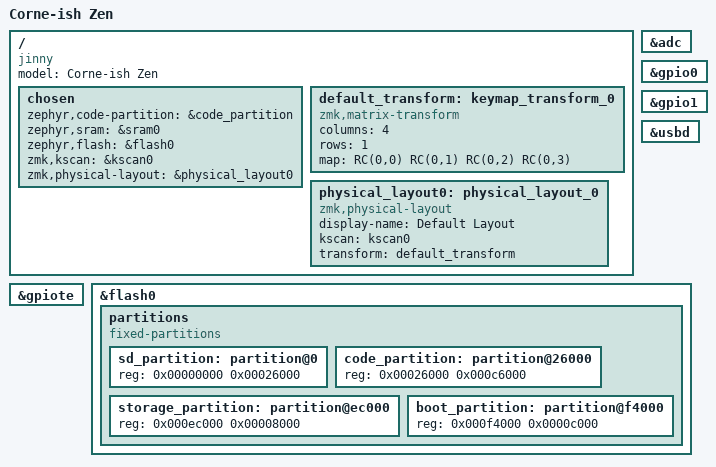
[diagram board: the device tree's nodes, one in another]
/*
*
* Copyright (c) 2021 Darryl deHaan
* SPDX-License-Identifier: MIT
*
*/

/dts-v1/;
#include <nordic/nrf52840_qiaa.dtsi>

#include <dt-bindings/zmk/matrix_transform.h>

/ {
    model = "Corne-ish Zen";
    compatible = "jinny";

    chosen {
        zephyr,code-partition = &code_partition;
        zephyr,sram = &sram0;
        zephyr,flash = &flash0;
        zmk,kscan = &kscan0;
        zmk,physical-layout = &physical_layout0;
    };

    default_transform: keymap_transform_0 {
        compatible = "zmk,matrix-transform";
        columns = <4>;
        rows = <1>;

            // | SW1  | SW2  | SW3  | SW4
                    map = <
            RC(0,0) RC(0,1) RC(0,2) RC(0,3)
        >;
    };

    physical_layout0: physical_layout_0 {
        compatible = "zmk,physical-layout";
        display-name = "Default Layout";
        kscan = <&kscan0>;
        transform = <&default_transform>;
    };

};

&adc {
    status = "okay";
};

&gpiote {
    status = "okay";
};

&gpio0 {
    status = "okay";
};

&gpio1 {
    status = "okay";
};

zephyr_udc0: &usbd {
    status = "okay";
};

&flash0 {
    /*
     * For more information, see:
     * http://docs.zephyrproject.org/latest/devices/dts/flash_partitions.html
     */
    partitions {
        compatible = "fixed-partitions";
        #address-cells = <1>;
        #size-cells = <1>;

        sd_partition: partition@0 {
            reg = <0x00000000 0x00026000>;
        };
        code_partition: partition@26000 {
            reg = <0x00026000 0x000c6000>;
        };

        /*
         * The flash starting at 0x000ec000 and ending at
         * 0x000f3fff is reserved for use by the application.
         */

        /*
         * Storage partition will be used by FCB/LittleFS/NVS
         * if enabled.
         */
        storage_partition: partition@ec000 {
            reg = <0x000ec000 0x00008000>;
        };

        boot_partition: partition@f4000 {
            reg = <0x000f4000 0x0000c000>;
        };
    };
};
